# HC32K118 register map
File version: 1.0
CPU: CM0+ r0p1, little endian, no MPU, no FPU, 2 interrupt priority bits
Registers are 32-bit, read-write, reset 0x0 unless marked. A register's access mark holds for its fields unless they carry their own. Offsets are from the block's base; [hi:lo] are bit positions; {n}, {i} and the like mark numbered series.

## MCAN
Base 0x40011400
0x04 ENDN reset 0x87654321
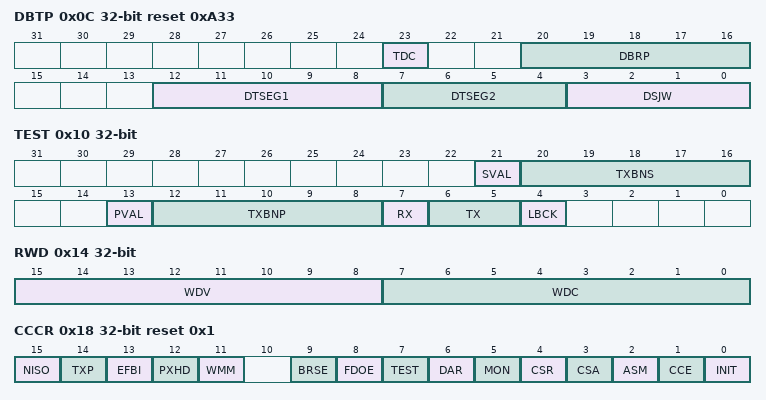
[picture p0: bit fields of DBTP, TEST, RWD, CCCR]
0x0C DBTP reset 0xA33
  [23] TDC, [20:16] DBRP, [12:8] DTSEG1, [7:4] DTSEG2, [3:0] DSJW
0x10 TEST
  [21] SVAL ro, [20:16] TXBNS ro, [13] PVAL ro, [12:8] TXBNP ro, [7] RX ro, [6:5] TX, [4] LBCK
0x14 RWD
  [15:8] WDV ro, [7:0] WDC
0x18 CCCR reset 0x1
  [15] NISO, [14] TXP, [13] EFBI, [12] PXHD, [11] WMM, [9] BRSE, [8] FDOE, [7] TEST, [6] DAR, [5] MON, [4] CSR, [3] CSA ro, [2] ASM, [1] CCE, [0] INIT
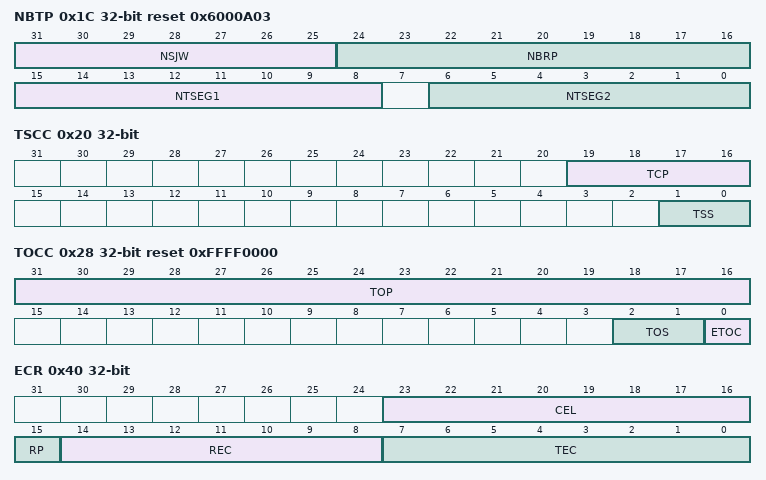
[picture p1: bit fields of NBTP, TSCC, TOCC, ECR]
0x1C NBTP reset 0x6000A03
  [31:25] NSJW, [24:16] NBRP, [15:8] NTSEG1, [6:0] NTSEG2
0x20 TSCC
  [19:16] TCP, [1:0] TSS
0x24 TSCV
  [15:0] TSC
0x28 TOCC reset 0xFFFF0000
  [31:16] TOP, [2:1] TOS, [0] ETOC
0x2C TOCV reset 0xFFFF
  [15:0] TOC
0x40 ECR ro
  [23:16] CEL, [15] RP, [14:8] REC, [7:0] TEC
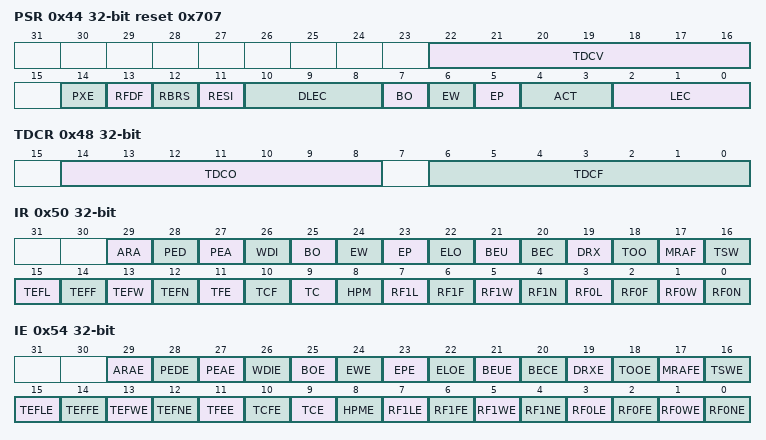
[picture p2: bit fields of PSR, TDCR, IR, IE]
0x44 PSR ro reset 0x707
  [22:16] TDCV, [14] PXE, [13] RFDF, [12] RBRS, [11] RESI, [10:8] DLEC, [7] BO, [6] EW, [5] EP, [4:3] ACT, [2:0] LEC
0x48 TDCR
  [14:8] TDCO, [6:0] TDCF
0x50 IR
  [29] ARA, [28] PED, [27] PEA, [26] WDI, [25] BO, [24] EW, [23] EP, [22] ELO, [21] BEU, [20] BEC, [19] DRX, [18] TOO, [17] MRAF, [16] TSW, [15] TEFL, [14] TEFF, [13] TEFW, [12] TEFN, [11] TFE, [10] TCF, [9] TC, [8] HPM, [7] RF1L, [6] RF1F, [5] RF1W, [4] RF1N, [3] RF0L, [2] RF0F, [1] RF0W, [0] RF0N
0x54 IE
  [29] ARAE, [28] PEDE, [27] PEAE, [26] WDIE, [25] BOE, [24] EWE, [23] EPE, [22] ELOE, [21] BEUE, [20] BECE, [19] DRXE, [18] TOOE, [17] MRAFE, [16] TSWE, [15] TEFLE, [14] TEFFE, [13] TEFWE, [12] TEFNE, [11] TFEE, [10] TCFE, [9] TCE, [8] HPME, [7] RF1LE, [6] RF1FE, [5] RF1WE, [4] RF1NE, [3] RF0LE, [2] RF0FE, [1] RF0WE, [0] RF0NE
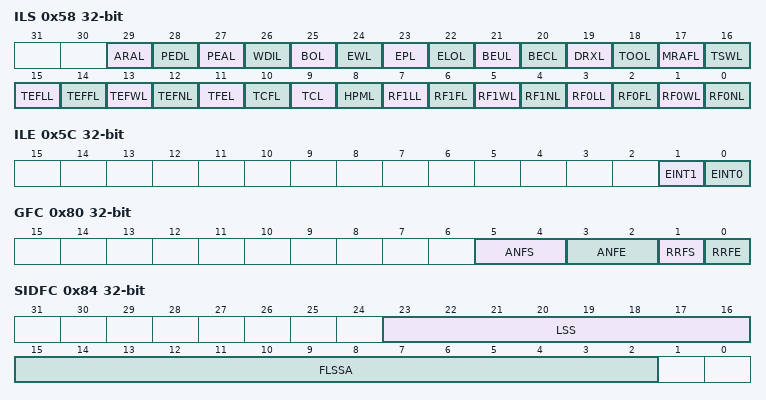
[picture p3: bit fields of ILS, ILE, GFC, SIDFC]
0x58 ILS
  [29] ARAL, [28] PEDL, [27] PEAL, [26] WDIL, [25] BOL, [24] EWL, [23] EPL, [22] ELOL, [21] BEUL, [20] BECL, [19] DRXL, [18] TOOL, [17] MRAFL, [16] TSWL, [15] TEFLL, [14] TEFFL, [13] TEFWL, [12] TEFNL, [11] TFEL, [10] TCFL, [9] TCL, [8] HPML, [7] RF1LL, [6] RF1FL, [5] RF1WL, [4] RF1NL, [3] RF0LL, [2] RF0FL, [1] RF0WL, [0] RF0NL
0x5C ILE
  [1] EINT1, [0] EINT0
0x80 GFC
  [5:4] ANFS, [3:2] ANFE, [1] RRFS, [0] RRFE
0x84 SIDFC
  [23:16] LSS, [15:2] FLSSA
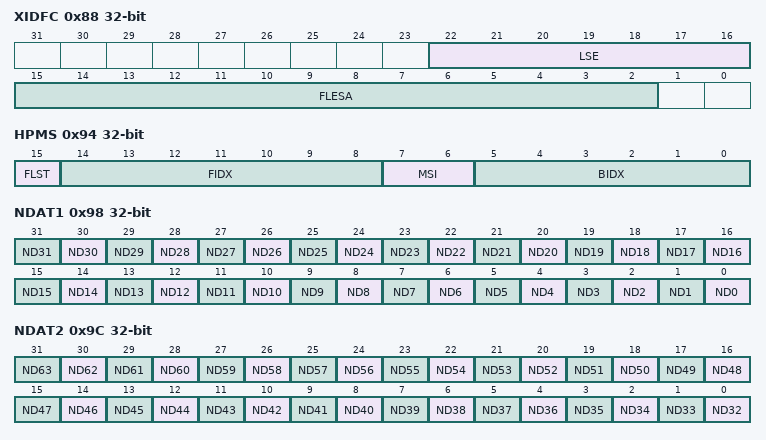
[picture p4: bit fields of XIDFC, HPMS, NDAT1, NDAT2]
0x88 XIDFC
  [22:16] LSE, [15:2] FLESA
0x90 XIDAM reset 0x1FFFFFFF
  [28:0] EIDM
0x94 HPMS ro
  [15] FLST, [14:8] FIDX, [7:6] MSI, [5:0] BIDX
0x98 NDAT1
  [n] ND{n} (n=0..31)
0x9C NDAT2
  [n-32] ND{n} (n=32..63)
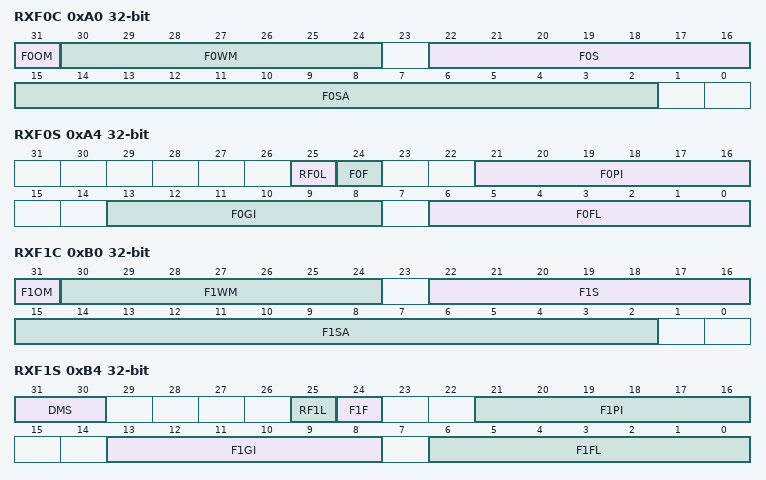
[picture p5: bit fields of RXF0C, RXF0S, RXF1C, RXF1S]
0xA0 RXF0C
  [31] F0OM, [30:24] F0WM, [22:16] F0S, [15:2] F0SA
0xA4 RXF0S ro
  [25] RF0L, [24] F0F, [21:16] F0PI, [13:8] F0GI, [6:0] F0FL
0xA8 RXF0A
  [5:0] F0AI
0xAC RXBC
  [15:2] RBSA
0xB0 RXF1C
  [31] F1OM, [30:24] F1WM, [22:16] F1S, [15:2] F1SA
0xB4 RXF1S ro
  [31:30] DMS, [25] RF1L, [24] F1F, [21:16] F1PI, [13:8] F1GI, [6:0] F1FL
0xB8 RXF1A
  [5:0] F1AI
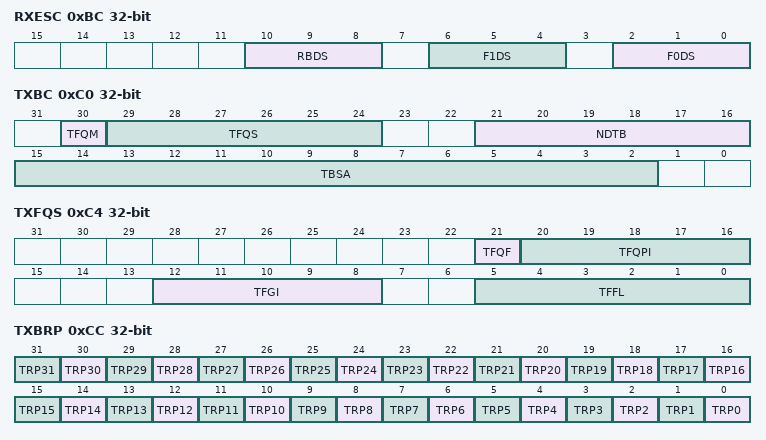
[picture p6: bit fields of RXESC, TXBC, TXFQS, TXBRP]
0xBC RXESC
  [10:8] RBDS, [6:4] F1DS, [2:0] F0DS
0xC0 TXBC
  [30] TFQM, [29:24] TFQS, [21:16] NDTB, [15:2] TBSA
0xC4 TXFQS ro
  [21] TFQF, [20:16] TFQPI, [12:8] TFGI, [5:0] TFFL
0xC8 TXESC
  [2:0] TBDS
0xCC TXBRP ro
  [n] TRP{n} (n=0..31)
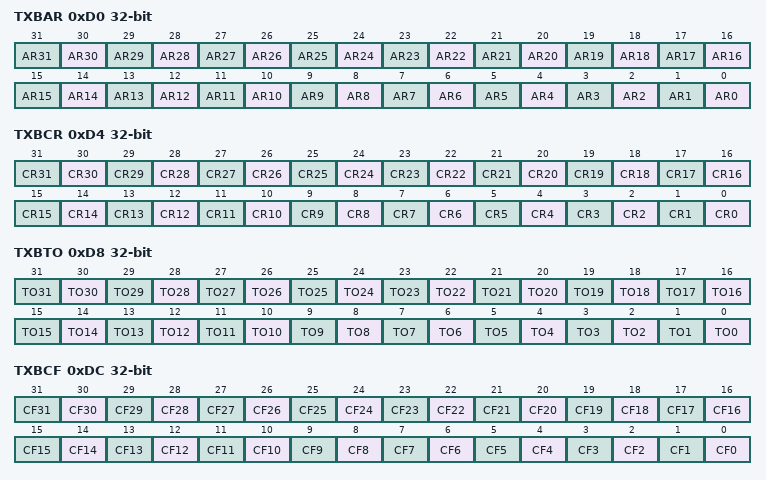
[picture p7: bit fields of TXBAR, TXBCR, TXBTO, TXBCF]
0xD0 TXBAR
  [n] AR{n} (n=0..31)
0xD4 TXBCR
  [n] CR{n} (n=0..31)
0xD8 TXBTO ro
  [n] TO{n} (n=0..31)
0xDC TXBCF ro
  [n] CF{n} (n=0..31)
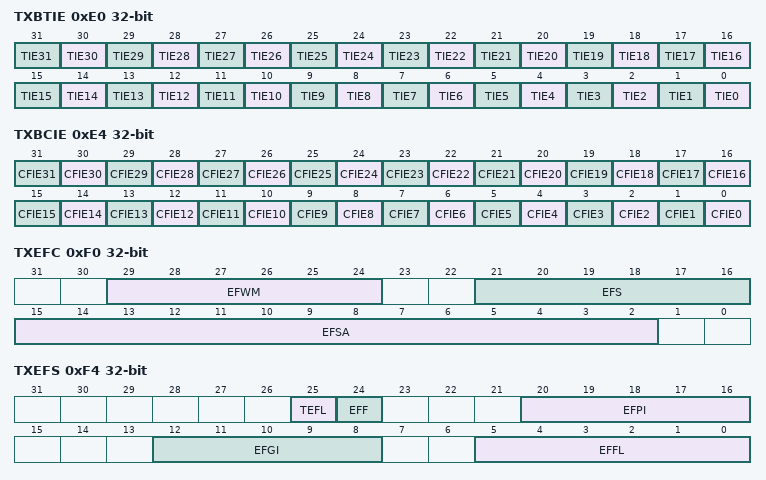
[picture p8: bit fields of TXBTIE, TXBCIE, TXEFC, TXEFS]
0xE0 TXBTIE
  [n] TIE{n} (n=0..31)
0xE4 TXBCIE
  [n] CFIE{n} (n=0..31)
0xF0 TXEFC
  [29:24] EFWM, [21:16] EFS, [15:2] EFSA
0xF4 TXEFS ro
  [25] TEFL, [24] EFF, [20:16] EFPI, [12:8] EFGI, [5:0] EFFL
0xF8 TXEFA
  [4:0] EFAI

## MCANRAM
Base 0x40011800
0x00 CKCR
  [1:0] ECCMOD
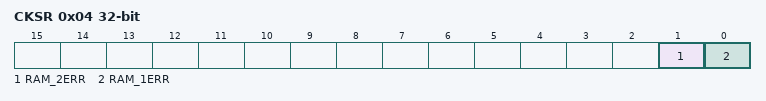
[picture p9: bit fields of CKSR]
0x04 CKSR
  [1] RAM_2ERR, [0] RAM_1ERR
0x08 EIEN
  [0] EIEN
0x0C EIBIT0
0x10 EIBIT1
  [6:0] EIBIT
0x14 ECCERRADDR ro
  [10:0] ECCERRADDR

## PERIC
Base 0x40013400
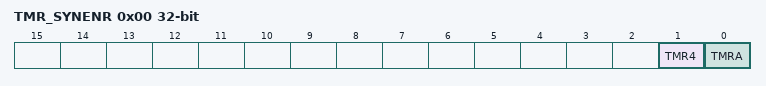
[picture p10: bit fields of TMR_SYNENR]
0x00 TMR_SYNENR
  [1] TMR4, [0] TMRA

## PWC
Base 0x40014000
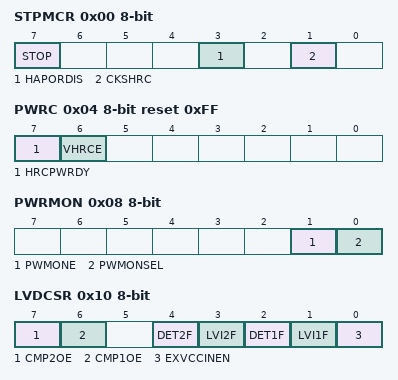
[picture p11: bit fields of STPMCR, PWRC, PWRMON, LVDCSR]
0x00 STPMCR 8-bit
  [7] STOP, [3] HAPORDIS, [1] CKSHRC
0x04 PWRC 8-bit reset 0xFF
  [7] HRCPWRDY, [6] VHRCE
0x08 PWRMON 8-bit
  [1] PWMONE, [0] PWMONSEL
0x0C RAMCR 8-bit
  [1:0] RPRTA
0x10 LVDCSR 8-bit
  [7] CMP2OE, [6] CMP1OE, [4] DET2F, [3] LVI2F, [2] DET1F, [1] LVI1F, [0] EXVCCINEN
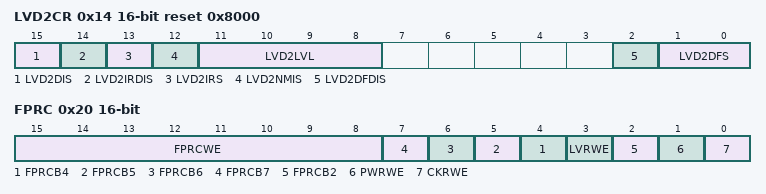
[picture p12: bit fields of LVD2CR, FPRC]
0x14 LVD2CR 16-bit reset 0x8000
  [15] LVD2DIS, [14] LVD2IRDIS, [13] LVD2IRS, [12] LVD2NMIS, [11:8] LVD2LVL, [2] LVD2DFDIS, [1:0] LVD2DFS
0x18 LPMCSR 16-bit ro
  [0] LPMF
0x1A LPMCSCR 16-bit
  [0] LPMFC
0x20 FPRC 16-bit
  [15:8] FPRCWE, [n] FPRCB{n} (n=4..7), [3] LVRWE, [2] FPRCB2, [1] PWRWE, [0] CKRWE
0x40 DBGC 8-bit
  [0] DBGEN
